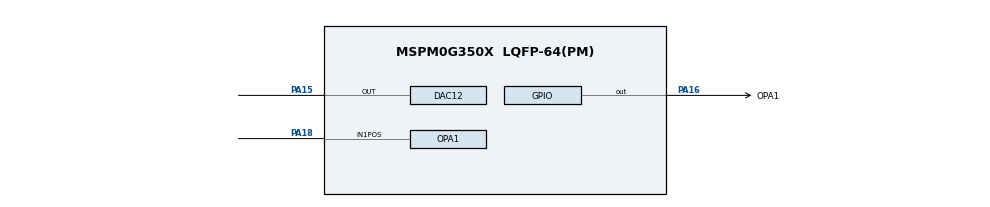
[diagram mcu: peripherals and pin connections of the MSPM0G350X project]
/**
 * @cliArgs --device "MSPM0G350X" --part "Default" --package "LQFP-64(PM)" --product "mspm0_sdk@2.09.00.02"
 * @versions {"tool":"1.25.0+4268"}
 */

/**
 * Import the modules used in this configuration.
 */
const ADC12         = scripting.addModule("/ti/driverlib/ADC12", {}, false);
const ADC121        = ADC12.addInstance();
const DAC12         = scripting.addModule("/ti/driverlib/DAC12");
const GPIO          = scripting.addModule("/ti/driverlib/GPIO", {}, false);
const GPIO1         = GPIO.addInstance();
const OPA           = scripting.addModule("/ti/driverlib/OPA", {}, false);
const OPA1          = OPA.addInstance();
const SYSCTL        = scripting.addModule("/ti/driverlib/SYSCTL");
const ProjectConfig = scripting.addModule("/ti/project_config/ProjectConfig");

/**
 * Write custom configuration values to the imported modules.
 */
ADC121.$name              = "ADC12_0";
ADC121.sampClkDiv         = "DL_ADC12_CLOCK_DIVIDE_8";
ADC121.adcMem0chansel     = "DL_ADC12_INPUT_CHAN_13";
ADC121.enabledInterrupts  = ["DL_ADC12_INTERRUPT_MEM0_RESULT_LOADED"];
ADC121.sampClkSrc         = "DL_ADC12_CLOCK_ULPCLK";
ADC121.sampleTime0        = "125us";
ADC121.powerDownMode      = "DL_ADC12_POWER_DOWN_MODE_MANUAL";
ADC121.peripheral.$assign = "ADC1";

const Board = scripting.addModule("/ti/driverlib/Board", {}, false);

DAC12.dacOutputPinEn            = true;
DAC12.dacAmplifier              = "ON";
DAC12.peripheral.$assign        = "DAC0";
DAC12.peripheral.OutPin.$assign = "PA15";
DAC12.OutPinConfig.$name        = "ti_driverlib_gpio_GPIOPinGeneric2";

GPIO1.port                          = "PORTA";
GPIO1.portSegment                   = "Upper";
GPIO1.$name                         = "PORTA_16";
GPIO1.associatedPins[0].$name       = "OPA1";
GPIO1.associatedPins[0].ioStructure = "SD";
GPIO1.associatedPins[0].pin.$assign = "PA16";

OPA1.$name                        = "OPA_0";
OPA1.cfg0PSELChannel              = "IN1_POS";
OPA1.cfg0NSELChannel              = "RTAP";
OPA1.cfg0MSELChannel              = "GND";
OPA1.cfg0Gain                     = "N7_P8";
OPA1.advBW                        = "HIGH";
OPA1.In1PosPinConfig.$name        = "ti_driverlib_gpio_GPIOPinGeneric0";
OPA1.peripheral.$assign           = "OPA1";
OPA1.peripheral.In1PosPin.$assign = "PA18";

SYSCTL.forceDefaultClkConfig = true;
SYSCTL.MFPCLKEn              = true;

/**
 * Pinmux solution for unlocked pins/peripherals. This ensures that minor changes to the automatic solver in a future
 * version of the tool will not impact the pinmux you originally saw.  These lines can be completely deleted in order to
 * re-solve from scratch.
 */
Board.peripheral.$suggestSolution          = "DEBUGSS";
Board.peripheral.swclkPin.$suggestSolution = "PA20";
Board.peripheral.swdioPin.$suggestSolution = "PA19";
SYSCTL.peripheral.$suggestSolution         = "SYSCTL";
